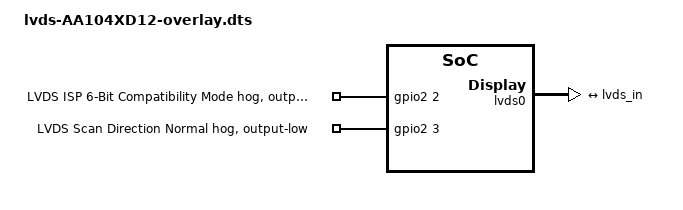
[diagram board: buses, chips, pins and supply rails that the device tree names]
/*
 * Device Tree Source for the Kingfisher (ULCB extension) LVDS panel
 *
 * Copyright (C) 2018 Renesas Electronics Corp.
 * Copyright (C) 2018 Cogent Embedded, Inc.
 * Copyright (C) 2019 GlobalLogic
 *
 * This file is licensed under the terms of the GNU General Public License
 * version 2.  This program is licensed "as is" without any warranty of any
 * kind, whether express or implied.
 */

/dts-v1/;
/plugin/;

#include <dt-bindings/gpio/gpio.h>

&lvds {
	compatible = "panel-lvds";

	width-mm = <210>;
	height-mm = <158>;

	data-mapping = "jeida-24";

	panel-timing {
		/* 1024x768 @60Hz Mitsubishi AA104XD12 compatible panel */
		clock-frequency = <65000000>;
		hactive = <1024>;
		vactive = <768>;
		hsync-len = <136>;
		hfront-porch = <20>;
		hback-porch = <160>;
		vfront-porch = <3>;
		vback-porch = <29>;
		vsync-len = <6>;
	};
};

&gpio2 {
	mode {
		gpio-hog;
		gpios = <2 GPIO_ACTIVE_HIGH>;
		output-low;
		line-name = "LVDS ISP 6-Bit Compatibility Mode";
	};

	sd {
		gpio-hog;
		gpios = <3 GPIO_ACTIVE_HIGH>;
		output-low;
		line-name = "LVDS Scan Direction Normal";
	};
};

&lvds0 {
	ports {
		port@1 {
			lvds0_out: endpoint {
				remote-endpoint = <&lvds_in>;
			};
		};
	};
};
